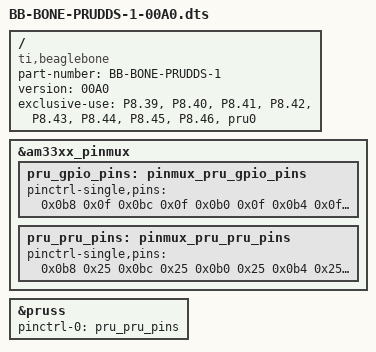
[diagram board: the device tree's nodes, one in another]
// generated by config.pl
// modify the top of that file, not this one
/dts-v1/;
/plugin/;

/ {
	compatible = "ti,beaglebone", "ti,beaglebone-black";

	/* identification */
	part-number = "BB-BONE-PRUDDS-1";
	version = "00A0";

	/* state the resources this cape uses */
	exclusive-use =
		/* the pin header uses */
		"P8.39",
		"P8.40",
		"P8.41",
		"P8.42",
		"P8.43",
		"P8.44",
		"P8.45",
		"P8.46",
		/* the hardware IP uses */
		"pru0";

	fragment@0 {
		target = <&am33xx_pinmux>;
		__overlay__ {

			pru_gpio_pins: pinmux_pru_gpio_pins {
				pinctrl-single,pins = <
		0x0b8 0x0f
		0x0bc 0x0f
		0x0b0 0x0f
		0x0b4 0x0f
		0x0a8 0x0f
		0x0ac 0x0f
		0x0a0 0x0f
		0x0a4 0x0f
				>;
			};

			pru_pru_pins: pinmux_pru_pru_pins {
				pinctrl-single,pins = <
		0x0b8 0x25
		0x0bc 0x25
		0x0b0 0x25
		0x0b4 0x25
		0x0a8 0x25
		0x0ac 0x25
		0x0a0 0x25
		0x0a4 0x25
				>;
			};
		};	
	};

	fragment@2 {
		target = <&pruss>;
		__overlay__ {
			status = "okay";

			pinctrl-names = "default";
			pinctrl-0 = <&pru_pru_pins>;
		};
	};
};
